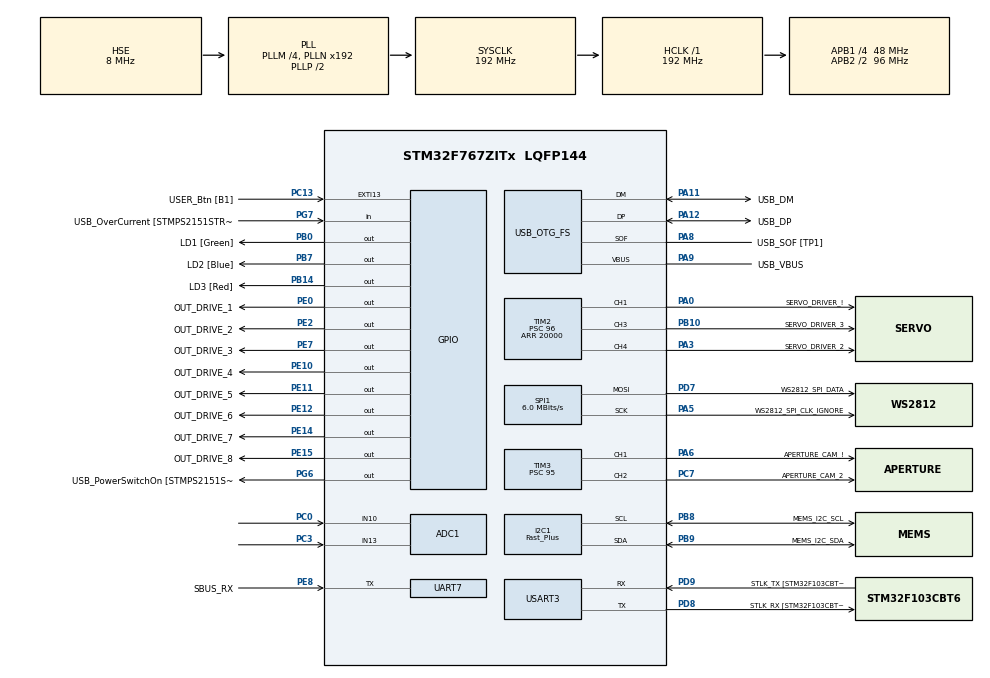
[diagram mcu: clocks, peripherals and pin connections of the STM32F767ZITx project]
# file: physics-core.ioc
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ADC1.Channel-0\#ChannelRegularConversion=ADC_CHANNEL_10
ADC1.NbrOfConversionFlag=1
ADC1.Rank-0\#ChannelRegularConversion=1
ADC1.SamplingTime-0\#ChannelRegularConversion=ADC_SAMPLETIME_3CYCLES
ADC1.master=1
CORTEX_M7.CPU_DCache=Enabled
CORTEX_M7.CPU_ICache=Enabled
CORTEX_M7.FlashInterface=TCM_Enabled
CRC.CRCLength=CRC_POLYLENGTH_16B
CRC.DefaultInitValueUse=DEFAULT_INIT_VALUE_DISABLE
CRC.DefaultPolynomialUse=DEFAULT_POLYNOMIAL_DISABLE
CRC.GeneratingPolynomial=X12+X5+X0
CRC.InitValue=0xffff
Dma.I2C1_RX.1.Direction=DMA_PERIPH_TO_MEMORY
Dma.I2C1_RX.1.FIFOMode=DMA_FIFOMODE_DISABLE
Dma.I2C1_RX.1.Instance=DMA1_Stream0
Dma.I2C1_RX.1.MemDataAlignment=DMA_MDATAALIGN_BYTE
Dma.I2C1_RX.1.MemInc=DMA_MINC_ENABLE
Dma.I2C1_RX.1.Mode=DMA_NORMAL
Dma.I2C1_RX.1.PeriphDataAlignment=DMA_PDATAALIGN_BYTE
Dma.I2C1_RX.1.PeriphInc=DMA_PINC_DISABLE
Dma.I2C1_RX.1.Priority=DMA_PRIORITY_HIGH
Dma.Request0=TIM8_UP
Dma.Request1=I2C1_RX
Dma.Request2=SPI1_TX
Dma.Request3=USART3_TX
Dma.Request4=UART7_RX
Dma.SPI1_TX.2.Direction=DMA_MEMORY_TO_PERIPH
Dma.SPI1_TX.2.FIFOMode=DMA_FIFOMODE_ENABLE
Dma.SPI1_TX.2.FIFOThreshold=DMA_FIFO_THRESHOLD_FULL
Dma.SPI1_TX.2.Instance=DMA2_Stream3
Dma.SPI1_TX.2.MemBurst=DMA_MBURST_INC16
Dma.SPI1_TX.2.MemDataAlignment=DMA_MDATAALIGN_BYTE
Dma.SPI1_TX.2.MemInc=DMA_MINC_ENABLE
Dma.SPI1_TX.2.Mode=DMA_NORMAL
Dma.SPI1_TX.2.PeriphBurst=DMA_PBURST_SINGLE
Dma.SPI1_TX.2.PeriphDataAlignment=DMA_PDATAALIGN_BYTE
Dma.SPI1_TX.2.PeriphInc=DMA_PINC_DISABLE
Dma.SPI1_TX.2.Priority=DMA_PRIORITY_LOW
Dma.TIM8_UP.0.Direction=DMA_MEMORY_TO_PERIPH
Dma.TIM8_UP.0.FIFOMode=DMA_FIFOMODE_ENABLE
Dma.TIM8_UP.0.FIFOThreshold=DMA_FIFO_THRESHOLD_FULL
Dma.TIM8_UP.0.Instance=DMA2_Stream1
Dma.TIM8_UP.0.MemBurst=DMA_MBURST_INC4
Dma.TIM8_UP.0.MemDataAlignment=DMA_MDATAALIGN_WORD
Dma.TIM8_UP.0.MemInc=DMA_MINC_ENABLE
Dma.TIM8_UP.0.Mode=DMA_NORMAL
Dma.TIM8_UP.0.PeriphBurst=DMA_PBURST_SINGLE
Dma.TIM8_UP.0.PeriphDataAlignment=DMA_PDATAALIGN_WORD
Dma.TIM8_UP.0.PeriphInc=DMA_PINC_DISABLE
Dma.TIM8_UP.0.Priority=DMA_PRIORITY_VERY_HIGH
Dma.UART7_RX.4.Direction=DMA_PERIPH_TO_MEMORY
Dma.UART7_RX.4.FIFOMode=DMA_FIFOMODE_DISABLE
Dma.UART7_RX.4.Instance=DMA1_Stream3
Dma.UART7_RX.4.MemDataAlignment=DMA_MDATAALIGN_HALFWORD
Dma.UART7_RX.4.MemInc=DMA_MINC_ENABLE
Dma.UART7_RX.4.Mode=DMA_CIRCULAR
Dma.UART7_RX.4.PeriphDataAlignment=DMA_PDATAALIGN_HALFWORD
Dma.UART7_RX.4.PeriphInc=DMA_PINC_DISABLE
Dma.UART7_RX.4.Priority=DMA_PRIORITY_VERY_HIGH
Dma.USART3_TX.3.Direction=DMA_MEMORY_TO_PERIPH
Dma.USART3_TX.3.FIFOMode=DMA_FIFOMODE_ENABLE
Dma.USART3_TX.3.FIFOThreshold=DMA_FIFO_THRESHOLD_FULL
Dma.USART3_TX.3.Instance=DMA1_Stream4
Dma.USART3_TX.3.MemBurst=DMA_MBURST_SINGLE
Dma.USART3_TX.3.MemDataAlignment=DMA_MDATAALIGN_BYTE
Dma.USART3_TX.3.MemInc=DMA_MINC_ENABLE
Dma.USART3_TX.3.Mode=DMA_NORMAL
Dma.USART3_TX.3.PeriphBurst=DMA_PBURST_SINGLE
Dma.USART3_TX.3.PeriphDataAlignment=DMA_PDATAALIGN_BYTE
Dma.USART3_TX.3.PeriphInc=DMA_PINC_DISABLE
Dma.USART3_TX.3.Priority=DMA_PRIORITY_LOW
I2C1.I2C_Speed_Mode=I2C_Fast_Plus
I2C1.Timing=0x20000209
Mcu.Family=STM32F7
Mcu.Name=STM32F767ZITx
Mcu.Package=LQFP144
NVIC.DMA1_Stream0_IRQn=true\:0\:0\:false\:false\:true\:false\:true
NVIC.DMA1_Stream3_IRQn=true\:0\:0\:false\:false\:true\:false\:true
NVIC.DMA1_Stream4_IRQn=true\:0\:0\:false\:false\:true\:false\:true
NVIC.DMA2_Stream1_IRQn=true\:0\:0\:false\:false\:true\:false\:true
NVIC.DMA2_Stream3_IRQn=true\:0\:0\:false\:false\:true\:false\:true
NVIC.OTG_FS_IRQn=true\:0\:0\:false\:false\:true\:false\:true
NVIC.PriorityGroup=NVIC_PRIORITYGROUP_4
NVIC.UART7_IRQn=true\:0\:0\:false\:false\:true\:true\:true
PA0/WKUP.GPIO_Label=SERVO_DRIVER_\!
PA0/WKUP.Signal=S_TIM2_CH1_ETR
PA1.GPIO_Label=RMII_REF_CLK [LAN8742A-CZ-TR_REFCLK0]
PA1.Signal=ETH_REF_CLK
PA10.GPIO_Label=USB_ID
PA10.Signal=USB_OTG_FS_ID
PA11.GPIO_Label=USB_DM
PA11.Mode=Device_Only
PA11.Signal=USB_OTG_FS_DM
PA12.GPIO_Label=USB_DP
PA12.Mode=Device_Only
PA12.Signal=USB_OTG_FS_DP
PA13.GPIO_Label=TMS
PA13.Mode=Serial_Wire
PA13.Signal=SYS_JTMS-SWDIO
PA14.GPIO_Label=TCK
PA14.Mode=Serial_Wire
PA14.Signal=SYS_JTCK-SWCLK
PA2.GPIO_Label=RMII_MDIO [LAN8742A-CZ-TR_MDIO]
PA2.Signal=ETH_MDIO
PA3.GPIO_Label=SERVO_DRIVER_2
PA3.Signal=S_TIM2_CH4
PA5.GPIO_Label=WS2812_SPI_CLK_IGNORE
PA5.Mode=TX_Only_Simplex_Unidirect_Master
PA5.Signal=SPI1_SCK
PA6.GPIO_Label=APERTURE_CAM_\!
PA6.GPIO_Speed=GPIO_SPEED_FREQ_VERY_HIGH
PA6.Signal=S_TIM3_CH1
PA7.GPIO_Label=RMII_CRS_DV [LAN8742A-CZ-TR_CRS_DV]
PA7.Signal=ETH_CRS_DV
PA8.GPIO_Label=USB_SOF [TP1]
PA8.Mode=Activate_SOF_FS
PA8.Signal=USB_OTG_FS_SOF
PA9.GPIO_Label=USB_VBUS
PA9.Mode=Activate_VBUS
PA9.Signal=USB_OTG_FS_VBUS
PB0.GPIO_Label=LD1 [Green]
PB0.Signal=GPIO_Output
PB10.GPIO_Label=SERVO_DRIVER_3
PB10.Signal=S_TIM2_CH3
PB13.GPIO_Label=RMII_TXD1 [LAN8742A-CZ-TR_TXD1]
PB13.Signal=ETH_TXD1
PB14.GPIO_Label=LD3 [Red]
PB14.Signal=GPIO_Output
PB3.GPIO_Label=SWO
PB3.Signal=SYS_JTDO-SWO
PB7.GPIO_Label=LD2 [Blue]
PB7.Signal=GPIO_Output
PB8.GPIO_Label=MEMS_I2C_SCL
PB8.Mode=I2C
PB8.Signal=I2C1_SCL
PB9.GPIO_Label=MEMS_I2C_SDA
PB9.Mode=I2C
PB9.Signal=I2C1_SDA
PC0.Signal=ADCx_IN10
PC1.GPIO_Label=RMII_MDC [LAN8742A-CZ-TR_MDC]
PC1.Signal=ETH_MDC
PC13.GPIO_Label=USER_Btn [B1]
PC13.Signal=GPXTI13
PC14/OSC32_IN.Mode=LSE-External-Oscillator
PC14/OSC32_IN.Signal=RCC_OSC32_IN
PC15/OSC32_OUT.Mode=LSE-External-Oscillator
PC15/OSC32_OUT.Signal=RCC_OSC32_OUT
PC3.Signal=ADCx_IN13
PC4.GPIO_Label=RMII_RXD0 [LAN8742A-CZ-TR_RXD0]
PC4.Signal=ETH_RXD0
PC5.GPIO_Label=RMII_RXD1 [LAN8742A-CZ-TR_RXD1]
PC5.Signal=ETH_RXD1
PC7.GPIO_Label=APERTURE_CAM_2
PC7.GPIO_Speed=GPIO_SPEED_FREQ_VERY_HIGH
PC7.Signal=S_TIM3_CH2
PD7.GPIO_Label=WS2812_SPI_DATA
PD7.Mode=TX_Only_Simplex_Unidirect_Master
PD7.Signal=SPI1_MOSI
PD8.GPIO_Label=STLK_RX [STM32F103CBT6_PA3]
PD8.Mode=Asynchronous
PD8.Signal=USART3_TX
PD9.GPIO_Label=STLK_TX [STM32F103CBT6_PA2]
PD9.Mode=Asynchronous
PD9.Signal=USART3_RX
PE0.GPIO_Label=OUT_DRIVE_1
PE0.GPIO_PuPd=GPIO_NOPULL
PE0.GPIO_Speed=GPIO_SPEED_FREQ_HIGH
PE0.Signal=GPIO_Output
PE10.GPIO_Label=OUT_DRIVE_4
PE10.GPIO_Speed=GPIO_SPEED_FREQ_HIGH
PE10.Signal=GPIO_Output
PE11.GPIO_Label=OUT_DRIVE_5
PE11.GPIO_Speed=GPIO_SPEED_FREQ_HIGH
PE11.Signal=GPIO_Output
PE12.GPIO_Label=OUT_DRIVE_6
PE12.GPIO_Speed=GPIO_SPEED_FREQ_HIGH
PE12.Signal=GPIO_Output
PE14.GPIO_Label=OUT_DRIVE_7
PE14.GPIO_Speed=GPIO_SPEED_FREQ_HIGH
PE14.Signal=GPIO_Output
PE15.GPIO_Label=OUT_DRIVE_8
PE15.GPIO_Speed=GPIO_SPEED_FREQ_HIGH
PE15.Signal=GPIO_Output
PE2.GPIO_Label=OUT_DRIVE_2
PE2.GPIO_Speed=GPIO_SPEED_FREQ_HIGH
PE2.Signal=GPIO_Output
PE7.GPIO_Label=OUT_DRIVE_3
PE7.GPIO_Speed=GPIO_SPEED_FREQ_HIGH
PE7.Signal=GPIO_Output
PE8.GPIO_Label=SBUS_RX
PE8.Mode=Half_duplex(single_wire_mode)
PE8.Signal=UART7_TX
PG11.GPIO_Label=RMII_TX_EN [LAN8742A-CZ-TR_TXEN]
PG11.Signal=ETH_TX_EN
PG13.GPIO_Label=RMII_TXD0 [LAN8742A-CZ-TR_TXD0]
PG13.Signal=ETH_TXD0
PG6.GPIO_Label=USB_PowerSwitchOn [STMPS2151STR_EN]
PG6.Signal=GPIO_Output
PG7.GPIO_Label=USB_OverCurrent [STMPS2151STR_FAULT]
PG7.Signal=GPIO_Input
PH0/OSC_IN.GPIO_Label=MCO [STM32F103CBT6_PA8]
PH0/OSC_IN.Mode=HSE-External-Clock-Source
PH0/OSC_IN.Signal=RCC_OSC_IN
PH1/OSC_OUT.Mode=HSE-External-Clock-Source
PH1/OSC_OUT.Signal=RCC_OSC_OUT
ProjectManager.HeapSize=0x2000
ProjectManager.StackSize=0x4000
ProjectManager.TargetToolchain=STM32CubeIDE
RCC.48MHZClocksFreq_Value=24000000
RCC.AHBFreq_Value=192000000
RCC.APB1CLKDivider=RCC_HCLK_DIV4
RCC.APB1Freq_Value=48000000
RCC.APB1TimFreq_Value=96000000
RCC.APB2CLKDivider=RCC_HCLK_DIV2
RCC.APB2Freq_Value=96000000
RCC.APB2TimFreq_Value=192000000
RCC.CortexFreq_Value=192000000
RCC.HCLKFreq_Value=192000000
RCC.HSE_VALUE=8000000
RCC.HSI_VALUE=16000000
RCC.PLLM=4
RCC.PLLMUL=RCC_PLL_MUL9
RCC.PLLQ=8
RCC.PRESCALERUSB=RCC_USBCLKSOURCE_PLL_DIV1_5
RCC.SYSCLKFreq_VALUE=192000000
RCC.SYSCLKSource=RCC_SYSCLKSOURCE_PLLCLK
RCC.SYSCLKSourceVirtual=RCC_SYSCLKSOURCE_PLLCLK
RCC.USBFreq_Value=48000000
RCC.VCOOutputFreq_Value=384000000
SH.ADCx_IN10.0=ADC1_IN10,IN10
SH.ADCx_IN13.0=ADC1_IN13,IN13
SH.S_TIM2_CH1_ETR.0=TIM2_CH1,PWM Generation1 CH1
SH.S_TIM2_CH3.0=TIM2_CH3,PWM Generation3 CH3
SH.S_TIM2_CH4.0=TIM2_CH4,PWM Generation4 CH4
SH.S_TIM3_CH1.0=TIM3_CH1,PWM Generation1 CH1
SH.S_TIM3_CH2.0=TIM3_CH2,PWM Generation2 CH2
SPI1.BaudRatePrescaler=SPI_BAUDRATEPRESCALER_16
SPI1.CalculateBaudRate=6.0 MBits/s
SPI1.DataSize=SPI_DATASIZE_6BIT
SPI1.Direction=SPI_DIRECTION_2LINES
SPI1.Mode=SPI_MODE_MASTER
SPI1.NSSPMode=SPI_NSS_PULSE_DISABLE
SPI1.VirtualType=VM_MASTER
TIM2.AutoReloadPreload=TIM_AUTORELOAD_PRELOAD_ENABLE
TIM2.Channel-PWM\ Generation1\ CH1=TIM_CHANNEL_1
TIM2.Channel-PWM\ Generation3\ CH3=TIM_CHANNEL_3
TIM2.Channel-PWM\ Generation4\ CH4=TIM_CHANNEL_4
TIM2.OC1Preload_PWM=ENABLE
TIM2.OCFastMode_PWM-PWM\ Generation1\ CH1=TIM_OCFAST_ENABLE
TIM2.OCFastMode_PWM-PWM\ Generation3\ CH3=TIM_OCFAST_ENABLE
TIM2.OCFastMode_PWM-PWM\ Generation4\ CH4=TIM_OCFAST_ENABLE
TIM2.Period=20000
TIM2.Prescaler=96
TIM2.Pulse-PWM\ Generation1\ CH1=1500
TIM2.Pulse-PWM\ Generation3\ CH3=1500
TIM2.Pulse-PWM\ Generation4\ CH4=1500
TIM3.AutoReloadPreload=TIM_AUTORELOAD_PRELOAD_ENABLE
TIM3.Channel-PWM\ Generation1\ CH1=TIM_CHANNEL_1
TIM3.Channel-PWM\ Generation2\ CH2=TIM_CHANNEL_2
TIM3.OCFastMode_PWM-PWM\ Generation1\ CH1=TIM_OCFAST_ENABLE
TIM3.OCFastMode_PWM-PWM\ Generation2\ CH2=TIM_OCFAST_ENABLE
TIM3.OCPolarity_1=TIM_OCPOLARITY_HIGH
TIM3.OCPolarity_2=TIM_OCPOLARITY_HIGH
TIM3.Period=99
TIM3.Prescaler=95
TIM3.Pulse-PWM\ Generation1\ CH1=0
TIM3.Pulse-PWM\ Generation2\ CH2=0
TIM8.AutoReloadPreload=TIM_AUTORELOAD_PRELOAD_ENABLE
TIM8.Period=4
TIM8.Prescaler=7
UART7.BaudRate=100000
UART7.DataInvertParam=UART_ADVFEATURE_DATAINV_DISABLE
UART7.Mode=MODE_RX
UART7.Parity=PARITY_EVEN
UART7.RxPinLevelInvertParam=UART_ADVFEATURE_RXINV_ENABLE
UART7.StopBits=UART_STOPBITS_2
UART7.TxPinLevelInvertParam=UART_ADVFEATURE_TXINV_ENABLE
UART7.WordLength=WORDLENGTH_9B
USART3.VirtualMode-Asynchronous=VM_ASYNC
USB_DEVICE.CLASS_NAME_FS=CDC
USB_DEVICE.VirtualMode-CDC_FS=Cdc
USB_DEVICE.VirtualModeFS=Cdc_FS
USB_OTG_FS.VirtualMode=Device_Only
VP_ADC1_TempSens_Input.Mode=IN-TempSens
VP_CRC_VS_CRC.Mode=CRC_Activate
VP_TIM2_VS_ClockSourceINT.Mode=Internal
VP_TIM3_VS_ClockSourceINT.Mode=Internal
VP_TIM8_VS_ClockSourceINT.Mode=Internal
VP_USB_DEVICE_VS_USB_DEVICE_CDC_FS.Mode=CDC_FS
board=NUCLEO-F767ZI

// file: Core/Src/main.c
/* USER CODE BEGIN Header */
/**
 ******************************************************************************
 * @file           : main.c
 * @brief          : Main program body
 ******************************************************************************
 * @attention
 *
 * <h2><center>&copy; Copyright (c) 2020 STMicroelectronics.
 * All rights reserved.</center></h2>
 *
 * This software component is licensed by ST under BSD 3-Clause license,
 * the "License"; You may not use this file except in compliance with the
 * License. You may obtain a copy of the License at:
 *                        opensource.org/licenses/BSD-3-Clause
 *
 ******************************************************************************
 */
/* USER CODE END Header */
#include "main.h"
#include "usb_device.h"

ADC_HandleTypeDef hadc1;

CRC_HandleTypeDef hcrc;

I2C_HandleTypeDef hi2c1;
DMA_HandleTypeDef hdma_i2c1_rx;

SPI_HandleTypeDef hspi1;
DMA_HandleTypeDef hdma_spi1_tx;

TIM_HandleTypeDef htim2;
TIM_HandleTypeDef htim3;
TIM_HandleTypeDef htim8;
DMA_HandleTypeDef hdma_tim8_up;

UART_HandleTypeDef huart7;
UART_HandleTypeDef huart3;
DMA_HandleTypeDef hdma_uart7_rx;
DMA_HandleTypeDef hdma_usart3_tx;

/* USER CODE BEGIN PV */
csm_core_t csmc;
/* USER CODE END PV */

void SystemClock_Config(void);
static void MX_GPIO_Init(void);
static void MX_DMA_Init(void);
static void MX_USART3_UART_Init(void);
static void MX_TIM3_Init(void);
static void MX_CRC_Init(void);
static void MX_TIM8_Init(void);
static void MX_I2C1_Init(void);
static void MX_TIM2_Init(void);
static void MX_SPI1_Init(void);
static void MX_UART7_Init(void);
static void MX_ADC1_Init(void);

int main(void)
{

  /* Enable I-Cache---------------------------------------------------------*/
  SCB_EnableICache();

  /* Enable D-Cache---------------------------------------------------------*/
  SCB_EnableDCache();

  /* MCU Configuration--------------------------------------------------------*/

  /* Reset of all peripherals, Initializes the Flash interface and the Systick. */
  HAL_Init();

  /* Configure the system clock */
  SystemClock_Config();

  /* Initialize all configured peripherals */
  MX_GPIO_Init();
  MX_DMA_Init();
  MX_USART3_UART_Init();
  MX_TIM3_Init();
  MX_USB_DEVICE_Init();
  MX_CRC_Init();
  MX_TIM8_Init();
  MX_I2C1_Init();
  MX_TIM2_Init();
  MX_SPI1_Init();
  MX_UART7_Init();
  MX_ADC1_Init();
  /* USER CODE BEGIN 2 */

	pre_while();
  /* USER CODE END 2 */

  /* Infinite loop */
	while (1) {

    /* USER CODE BEGIN 3 */
		in_while();
	}
  /* USER CODE END 3 */
}

void SystemClock_Config(void)
{
  RCC_OscInitTypeDef RCC_OscInitStruct = {0};
  RCC_ClkInitTypeDef RCC_ClkInitStruct = {0};
  RCC_PeriphCLKInitTypeDef PeriphClkInitStruct = {0};

  /** Configure LSE Drive Capability
  */
  HAL_PWR_EnableBkUpAccess();
  /** Configure the main internal regulator output voltage
  */
  __HAL_RCC_PWR_CLK_ENABLE();
  __HAL_PWR_VOLTAGESCALING_CONFIG(PWR_REGULATOR_VOLTAGE_SCALE1);
  /** Initializes the RCC Oscillators according to the specified parameters
  * in the RCC_OscInitTypeDef structure.
  */
  RCC_OscInitStruct.OscillatorType = RCC_OSCILLATORTYPE_HSE;
  RCC_OscInitStruct.HSEState = RCC_HSE_BYPASS;
  RCC_OscInitStruct.PLL.PLLState = RCC_PLL_ON;
  RCC_OscInitStruct.PLL.PLLSource = RCC_PLLSOURCE_HSE;
  RCC_OscInitStruct.PLL.PLLM = 4;
  RCC_OscInitStruct.PLL.PLLN = 192;
  RCC_OscInitStruct.PLL.PLLP = RCC_PLLP_DIV2;
  RCC_OscInitStruct.PLL.PLLQ = 8;
  if (HAL_RCC_OscConfig(&RCC_OscInitStruct) != HAL_OK)
  {
    Error_Handler();
  }
  /** Activate the Over-Drive mode
  */
  if (HAL_PWREx_EnableOverDrive() != HAL_OK)
  {
    Error_Handler();
  }
  /** Initializes the CPU, AHB and APB buses clocks
  */
  RCC_ClkInitStruct.ClockType = RCC_CLOCKTYPE_HCLK|RCC_CLOCKTYPE_SYSCLK
                              |RCC_CLOCKTYPE_PCLK1|RCC_CLOCKTYPE_PCLK2;
  RCC_ClkInitStruct.SYSCLKSource = RCC_SYSCLKSOURCE_PLLCLK;
  RCC_ClkInitStruct.AHBCLKDivider = RCC_SYSCLK_DIV1;
  RCC_ClkInitStruct.APB1CLKDivider = RCC_HCLK_DIV4;
  RCC_ClkInitStruct.APB2CLKDivider = RCC_HCLK_DIV2;

  if (HAL_RCC_ClockConfig(&RCC_ClkInitStruct, FLASH_LATENCY_6) != HAL_OK)
  {
    Error_Handler();
  }
  PeriphClkInitStruct.PeriphClockSelection = RCC_PERIPHCLK_USART3|RCC_PERIPHCLK_UART7
                              |RCC_PERIPHCLK_I2C1|RCC_PERIPHCLK_CLK48;
  PeriphClkInitStruct.Usart3ClockSelection = RCC_USART3CLKSOURCE_PCLK1;
  PeriphClkInitStruct.Uart7ClockSelection = RCC_UART7CLKSOURCE_PCLK1;
  PeriphClkInitStruct.I2c1ClockSelection = RCC_I2C1CLKSOURCE_PCLK1;
  PeriphClkInitStruct.Clk48ClockSelection = RCC_CLK48SOURCE_PLL;
  if (HAL_RCCEx_PeriphCLKConfig(&PeriphClkInitStruct) != HAL_OK)
  {
    Error_Handler();
  }
}

static void MX_ADC1_Init(void)
{

  ADC_ChannelConfTypeDef sConfig = {0};

  /** Configure the global features of the ADC (Clock, Resolution, Data Alignment and number of conversion)
  */
  hadc1.Instance = ADC1;
  hadc1.Init.ClockPrescaler = ADC_CLOCK_SYNC_PCLK_DIV4;
  hadc1.Init.Resolution = ADC_RESOLUTION_12B;
  hadc1.Init.ScanConvMode = ADC_SCAN_DISABLE;
  hadc1.Init.ContinuousConvMode = DISABLE;
  hadc1.Init.DiscontinuousConvMode = DISABLE;
  hadc1.Init.ExternalTrigConvEdge = ADC_EXTERNALTRIGCONVEDGE_NONE;
  hadc1.Init.ExternalTrigConv = ADC_SOFTWARE_START;
  hadc1.Init.DataAlign = ADC_DATAALIGN_RIGHT;
  hadc1.Init.NbrOfConversion = 1;
  hadc1.Init.DMAContinuousRequests = DISABLE;
  hadc1.Init.EOCSelection = ADC_EOC_SINGLE_CONV;
  if (HAL_ADC_Init(&hadc1) != HAL_OK)
  {
    Error_Handler();
  }
  /** Configure for the selected ADC regular channel its corresponding rank in the sequencer and its sample time.
  */
  sConfig.Channel = ADC_CHANNEL_10;
  sConfig.Rank = ADC_REGULAR_RANK_1;
  sConfig.SamplingTime = ADC_SAMPLETIME_3CYCLES;
  if (HAL_ADC_ConfigChannel(&hadc1, &sConfig) != HAL_OK)
  {
    Error_Handler();
  }

}

static void MX_CRC_Init(void)
{

  hcrc.Instance = CRC;
  hcrc.Init.DefaultPolynomialUse = DEFAULT_POLYNOMIAL_DISABLE;
  hcrc.Init.DefaultInitValueUse = DEFAULT_INIT_VALUE_DISABLE;
  hcrc.Init.GeneratingPolynomial = 4129;
  hcrc.Init.CRCLength = CRC_POLYLENGTH_16B;
  hcrc.Init.InitValue = 0xffff;
  hcrc.Init.InputDataInversionMode = CRC_INPUTDATA_INVERSION_NONE;
  hcrc.Init.OutputDataInversionMode = CRC_OUTPUTDATA_INVERSION_DISABLE;
  hcrc.InputDataFormat = CRC_INPUTDATA_FORMAT_BYTES;
  if (HAL_CRC_Init(&hcrc) != HAL_OK)
  {
    Error_Handler();
  }

}

static void MX_I2C1_Init(void)
{

  hi2c1.Instance = I2C1;
  hi2c1.Init.Timing = 0x20000209;
  hi2c1.Init.OwnAddress1 = 0;
  hi2c1.Init.AddressingMode = I2C_ADDRESSINGMODE_7BIT;
  hi2c1.Init.DualAddressMode = I2C_DUALADDRESS_DISABLE;
  hi2c1.Init.OwnAddress2 = 0;
  hi2c1.Init.OwnAddress2Masks = I2C_OA2_NOMASK;
  hi2c1.Init.GeneralCallMode = I2C_GENERALCALL_DISABLE;
  hi2c1.Init.NoStretchMode = I2C_NOSTRETCH_DISABLE;
  if (HAL_I2C_Init(&hi2c1) != HAL_OK)
  {
    Error_Handler();
  }
  /** Configure Analogue filter
  */
  if (HAL_I2CEx_ConfigAnalogFilter(&hi2c1, I2C_ANALOGFILTER_ENABLE) != HAL_OK)
  {
    Error_Handler();
  }
  /** Configure Digital filter
  */
  if (HAL_I2CEx_ConfigDigitalFilter(&hi2c1, 0) != HAL_OK)
  {
    Error_Handler();
  }
  /** I2C Enable Fast Mode Plus
  */
  HAL_I2CEx_EnableFastModePlus(I2C_FASTMODEPLUS_I2C1);

}

static void MX_SPI1_Init(void)
{

  /* SPI1 parameter configuration*/
  hspi1.Instance = SPI1;
  hspi1.Init.Mode = SPI_MODE_MASTER;
  hspi1.Init.Direction = SPI_DIRECTION_2LINES;
  hspi1.Init.DataSize = SPI_DATASIZE_6BIT;
  hspi1.Init.CLKPolarity = SPI_POLARITY_LOW;
  hspi1.Init.CLKPhase = SPI_PHASE_1EDGE;
  hspi1.Init.NSS = SPI_NSS_SOFT;
  hspi1.Init.BaudRatePrescaler = SPI_BAUDRATEPRESCALER_16;
  hspi1.Init.FirstBit = SPI_FIRSTBIT_MSB;
  hspi1.Init.TIMode = SPI_TIMODE_DISABLE;
  hspi1.Init.CRCCalculation = SPI_CRCCALCULATION_DISABLE;
  hspi1.Init.CRCPolynomial = 7;
  hspi1.Init.CRCLength = SPI_CRC_LENGTH_DATASIZE;
  hspi1.Init.NSSPMode = SPI_NSS_PULSE_DISABLE;
  if (HAL_SPI_Init(&hspi1) != HAL_OK)
  {
    Error_Handler();
  }

}

static void MX_TIM2_Init(void)
{

  TIM_ClockConfigTypeDef sClockSourceConfig = {0};
  TIM_MasterConfigTypeDef sMasterConfig = {0};
  TIM_OC_InitTypeDef sConfigOC = {0};

  htim2.Instance = TIM2;
  htim2.Init.Prescaler = 96;
  htim2.Init.CounterMode = TIM_COUNTERMODE_UP;
  htim2.Init.Period = 20000;
  htim2.Init.ClockDivision = TIM_CLOCKDIVISION_DIV1;
  htim2.Init.AutoReloadPreload = TIM_AUTORELOAD_PRELOAD_ENABLE;
  if (HAL_TIM_Base_Init(&htim2) != HAL_OK)
  {
    Error_Handler();
  }
  sClockSourceConfig.ClockSource = TIM_CLOCKSOURCE_INTERNAL;
  if (HAL_TIM_ConfigClockSource(&htim2, &sClockSourceConfig) != HAL_OK)
  {
    Error_Handler();
  }
  if (HAL_TIM_PWM_Init(&htim2) != HAL_OK)
  {
    Error_Handler();
  }
  sMasterConfig.MasterOutputTrigger = TIM_TRGO_RESET;
  sMasterConfig.MasterSlaveMode = TIM_MASTERSLAVEMODE_DISABLE;
  if (HAL_TIMEx_MasterConfigSynchronization(&htim2, &sMasterConfig) != HAL_OK)
  {
    Error_Handler();
  }
  sConfigOC.OCMode = TIM_OCMODE_PWM1;
  sConfigOC.Pulse = 1500;
  sConfigOC.OCPolarity = TIM_OCPOLARITY_HIGH;
  sConfigOC.OCFastMode = TIM_OCFAST_ENABLE;
  if (HAL_TIM_PWM_ConfigChannel(&htim2, &sConfigOC, TIM_CHANNEL_1) != HAL_OK)
  {
    Error_Handler();
  }
  if (HAL_TIM_PWM_ConfigChannel(&htim2, &sConfigOC, TIM_CHANNEL_3) != HAL_OK)
  {
    Error_Handler();
  }
  if (HAL_TIM_PWM_ConfigChannel(&htim2, &sConfigOC, TIM_CHANNEL_4) != HAL_OK)
  {
    Error_Handler();
  }
  HAL_TIM_MspPostInit(&htim2);

}

static void MX_TIM3_Init(void)
{

  TIM_ClockConfigTypeDef sClockSourceConfig = {0};
  TIM_MasterConfigTypeDef sMasterConfig = {0};
  TIM_OC_InitTypeDef sConfigOC = {0};

  htim3.Instance = TIM3;
  htim3.Init.Prescaler = 95;
  htim3.Init.CounterMode = TIM_COUNTERMODE_UP;
  htim3.Init.Period = 99;
  htim3.Init.ClockDivision = TIM_CLOCKDIVISION_DIV1;
  htim3.Init.AutoReloadPreload = TIM_AUTORELOAD_PRELOAD_ENABLE;
  if (HAL_TIM_Base_Init(&htim3) != HAL_OK)
  {
    Error_Handler();
  }
  sClockSourceConfig.ClockSource = TIM_CLOCKSOURCE_INTERNAL;
  if (HAL_TIM_ConfigClockSource(&htim3, &sClockSourceConfig) != HAL_OK)
  {
    Error_Handler();
  }
  if (HAL_TIM_PWM_Init(&htim3) != HAL_OK)
  {
    Error_Handler();
  }
  sMasterConfig.MasterOutputTrigger = TIM_TRGO_RESET;
  sMasterConfig.MasterSlaveMode = TIM_MASTERSLAVEMODE_DISABLE;
  if (HAL_TIMEx_MasterConfigSynchronization(&htim3, &sMasterConfig) != HAL_OK)
  {
    Error_Handler();
  }
  sConfigOC.OCMode = TIM_OCMODE_PWM1;
  sConfigOC.Pulse = 0;
  sConfigOC.OCPolarity = TIM_OCPOLARITY_HIGH;
  sConfigOC.OCFastMode = TIM_OCFAST_ENABLE;
  if (HAL_TIM_PWM_ConfigChannel(&htim3, &sConfigOC, TIM_CHANNEL_1) != HAL_OK)
  {
    Error_Handler();
  }
  if (HAL_TIM_PWM_ConfigChannel(&htim3, &sConfigOC, TIM_CHANNEL_2) != HAL_OK)
  {
    Error_Handler();
  }
  HAL_TIM_MspPostInit(&htim3);

}

static void MX_TIM8_Init(void)
{

  TIM_ClockConfigTypeDef sClockSourceConfig = {0};
  TIM_MasterConfigTypeDef sMasterConfig = {0};

  htim8.Instance = TIM8;
  htim8.Init.Prescaler = 7;
  htim8.Init.CounterMode = TIM_COUNTERMODE_UP;
  htim8.Init.Period = 4;
  htim8.Init.ClockDivision = TIM_CLOCKDIVISION_DIV1;
  htim8.Init.RepetitionCounter = 0;
  htim8.Init.AutoReloadPreload = TIM_AUTORELOAD_PRELOAD_ENABLE;
  if (HAL_TIM_Base_Init(&htim8) != HAL_OK)
  {
    Error_Handler();
  }
  sClockSourceConfig.ClockSource = TIM_CLOCKSOURCE_INTERNAL;
  if (HAL_TIM_ConfigClockSource(&htim8, &sClockSourceConfig) != HAL_OK)
  {
    Error_Handler();
  }
  sMasterConfig.MasterOutputTrigger = TIM_TRGO_RESET;
  sMasterConfig.MasterOutputTrigger2 = TIM_TRGO2_RESET;
  sMasterConfig.MasterSlaveMode = TIM_MASTERSLAVEMODE_DISABLE;
  if (HAL_TIMEx_MasterConfigSynchronization(&htim8, &sMasterConfig) != HAL_OK)
  {
    Error_Handler();
  }

}

static void MX_UART7_Init(void)
{

  huart7.Instance = UART7;
  huart7.Init.BaudRate = 100000;
  huart7.Init.WordLength = UART_WORDLENGTH_9B;
  huart7.Init.StopBits = UART_STOPBITS_2;
  huart7.Init.Parity = UART_PARITY_EVEN;
  huart7.Init.Mode = UART_MODE_RX;
  huart7.Init.HwFlowCtl = UART_HWCONTROL_NONE;
  huart7.Init.OverSampling = UART_OVERSAMPLING_16;
  huart7.Init.OneBitSampling = UART_ONE_BIT_SAMPLE_DISABLE;
  huart7.AdvancedInit.AdvFeatureInit = UART_ADVFEATURE_TXINVERT_INIT|UART_ADVFEATURE_RXINVERT_INIT;
  huart7.AdvancedInit.TxPinLevelInvert = UART_ADVFEATURE_TXINV_ENABLE;
  huart7.AdvancedInit.RxPinLevelInvert = UART_ADVFEATURE_RXINV_ENABLE;
  if (HAL_HalfDuplex_Init(&huart7) != HAL_OK)
  {
    Error_Handler();
  }

}

static void MX_USART3_UART_Init(void)
{

  huart3.Instance = USART3;
  huart3.Init.BaudRate = 115200;
  huart3.Init.WordLength = UART_WORDLENGTH_8B;
  huart3.Init.StopBits = UART_STOPBITS_1;
  huart3.Init.Parity = UART_PARITY_NONE;
  huart3.Init.Mode = UART_MODE_TX_RX;
  huart3.Init.HwFlowCtl = UART_HWCONTROL_NONE;
  huart3.Init.OverSampling = UART_OVERSAMPLING_16;
  huart3.Init.OneBitSampling = UART_ONE_BIT_SAMPLE_DISABLE;
  huart3.AdvancedInit.AdvFeatureInit = UART_ADVFEATURE_NO_INIT;
  if (HAL_UART_Init(&huart3) != HAL_OK)
  {
    Error_Handler();
  }

}

static void MX_DMA_Init(void)
{

  /* DMA controller clock enable */
  __HAL_RCC_DMA2_CLK_ENABLE();
  __HAL_RCC_DMA1_CLK_ENABLE();

  /* DMA interrupt init */
  /* DMA1_Stream0_IRQn interrupt configuration */
  HAL_NVIC_SetPriority(DMA1_Stream0_IRQn, 0, 0);
  HAL_NVIC_EnableIRQ(DMA1_Stream0_IRQn);
  /* DMA1_Stream3_IRQn interrupt configuration */
  HAL_NVIC_SetPriority(DMA1_Stream3_IRQn, 0, 0);
  HAL_NVIC_EnableIRQ(DMA1_Stream3_IRQn);
  /* DMA1_Stream4_IRQn interrupt configuration */
  HAL_NVIC_SetPriority(DMA1_Stream4_IRQn, 0, 0);
  HAL_NVIC_EnableIRQ(DMA1_Stream4_IRQn);
  /* DMA2_Stream1_IRQn interrupt configuration */
  HAL_NVIC_SetPriority(DMA2_Stream1_IRQn, 0, 0);
  HAL_NVIC_EnableIRQ(DMA2_Stream1_IRQn);
  /* DMA2_Stream3_IRQn interrupt configuration */
  HAL_NVIC_SetPriority(DMA2_Stream3_IRQn, 0, 0);
  HAL_NVIC_EnableIRQ(DMA2_Stream3_IRQn);

}

static void MX_GPIO_Init(void)
{
  GPIO_InitTypeDef GPIO_InitStruct = {0};

  /* GPIO Ports Clock Enable */
  __HAL_RCC_GPIOE_CLK_ENABLE();
  __HAL_RCC_GPIOC_CLK_ENABLE();
  __HAL_RCC_GPIOF_CLK_ENABLE();
  __HAL_RCC_GPIOH_CLK_ENABLE();
  __HAL_RCC_GPIOA_CLK_ENABLE();
  __HAL_RCC_GPIOB_CLK_ENABLE();
  __HAL_RCC_GPIOG_CLK_ENABLE();
  __HAL_RCC_GPIOD_CLK_ENABLE();

  /*Configure GPIO pin Output Level */
  HAL_GPIO_WritePin(GPIOE, OUT_DRIVE_2_Pin|OUT_DRIVE_3_Pin|OUT_DRIVE_4_Pin|OUT_DRIVE_5_Pin
                          |OUT_DRIVE_6_Pin|OUT_DRIVE_7_Pin|OUT_DRIVE_8_Pin|OUT_DRIVE_1_Pin, GPIO_PIN_RESET);

  /*Configure GPIO pin Output Level */
  HAL_GPIO_WritePin(GPIOB, LD1_Pin|LD3_Pin|LD2_Pin, GPIO_PIN_RESET);

  /*Configure GPIO pin Output Level */
  HAL_GPIO_WritePin(USB_PowerSwitchOn_GPIO_Port, USB_PowerSwitchOn_Pin, GPIO_PIN_RESET);

  /*Configure GPIO pins : OUT_DRIVE_2_Pin OUT_DRIVE_3_Pin OUT_DRIVE_4_Pin OUT_DRIVE_5_Pin
                           OUT_DRIVE_6_Pin OUT_DRIVE_7_Pin OUT_DRIVE_8_Pin OUT_DRIVE_1_Pin */
  GPIO_InitStruct.Pin = OUT_DRIVE_2_Pin|OUT_DRIVE_3_Pin|OUT_DRIVE_4_Pin|OUT_DRIVE_5_Pin
                          |OUT_DRIVE_6_Pin|OUT_DRIVE_7_Pin|OUT_DRIVE_8_Pin|OUT_DRIVE_1_Pin;
  GPIO_InitStruct.Mode = GPIO_MODE_OUTPUT_PP;
  GPIO_InitStruct.Pull = GPIO_NOPULL;
  GPIO_InitStruct.Speed = GPIO_SPEED_FREQ_HIGH;
  HAL_GPIO_Init(GPIOE, &GPIO_InitStruct);

  /*Configure GPIO pins : PE3 PE4 PE5 PE6
                           PE9 PE13 PE1 */
  GPIO_InitStruct.Pin = GPIO_PIN_3|GPIO_PIN_4|GPIO_PIN_5|GPIO_PIN_6
                          |GPIO_PIN_9|GPIO_PIN_13|GPIO_PIN_1;
  GPIO_InitStruct.Mode = GPIO_MODE_ANALOG;
  GPIO_InitStruct.Pull = GPIO_NOPULL;
  HAL_GPIO_Init(GPIOE, &GPIO_InitStruct);

  /*Configure GPIO pin : USER_Btn_Pin */
  GPIO_InitStruct.Pin = USER_Btn_Pin;
  GPIO_InitStruct.Mode = GPIO_MODE_IT_RISING;
  GPIO_InitStruct.Pull = GPIO_NOPULL;
  HAL_GPIO_Init(USER_Btn_GPIO_Port, &GPIO_InitStruct);

  /*Configure GPIO pins : PF0 PF1 PF2 PF3
                           PF4 PF5 PF6 PF7
                           PF8 PF9 PF10 PF11
                           PF12 PF13 PF14 PF15 */
  GPIO_InitStruct.Pin = GPIO_PIN_0|GPIO_PIN_1|GPIO_PIN_2|GPIO_PIN_3
                          |GPIO_PIN_4|GPIO_PIN_5|GPIO_PIN_6|GPIO_PIN_7
                          |GPIO_PIN_8|GPIO_PIN_9|GPIO_PIN_10|GPIO_PIN_11
                          |GPIO_PIN_12|GPIO_PIN_13|GPIO_PIN_14|GPIO_PIN_15;
  GPIO_InitStruct.Mode = GPIO_MODE_ANALOG;
  GPIO_InitStruct.Pull = GPIO_NOPULL;
  HAL_GPIO_Init(GPIOF, &GPIO_InitStruct);

  /*Configure GPIO pins : RMII_MDC_Pin RMII_RXD0_Pin RMII_RXD1_Pin */
  GPIO_InitStruct.Pin = RMII_MDC_Pin|RMII_RXD0_Pin|RMII_RXD1_Pin;
  GPIO_InitStruct.Mode = GPIO_MODE_AF_PP;
  GPIO_InitStruct.Pull = GPIO_NOPULL;
  GPIO_InitStruct.Speed = GPIO_SPEED_FREQ_VERY_HIGH;
  GPIO_InitStruct.Alternate = GPIO_AF11_ETH;
  HAL_GPIO_Init(GPIOC, &GPIO_InitStruct);

  /*Configure GPIO pins : PC2 PC6 PC8 PC9
                           PC10 PC11 PC12 */
  GPIO_InitStruct.Pin = GPIO_PIN_2|GPIO_PIN_6|GPIO_PIN_8|GPIO_PIN_9
                          |GPIO_PIN_10|GPIO_PIN_11|GPIO_PIN_12;
  GPIO_InitStruct.Mode = GPIO_MODE_ANALOG;
  GPIO_InitStruct.Pull = GPIO_NOPULL;
  HAL_GPIO_Init(GPIOC, &GPIO_InitStruct);

  /*Configure GPIO pins : RMII_REF_CLK_Pin RMII_MDIO_Pin RMII_CRS_DV_Pin */
  GPIO_InitStruct.Pin = RMII_REF_CLK_Pin|RMII_MDIO_Pin|RMII_CRS_DV_Pin;
  GPIO_InitStruct.Mode = GPIO_MODE_AF_PP;
  GPIO_InitStruct.Pull = GPIO_NOPULL;
  GPIO_InitStruct.Speed = GPIO_SPEED_FREQ_VERY_HIGH;
  GPIO_InitStruct.Alternate = GPIO_AF11_ETH;
  HAL_GPIO_Init(GPIOA, &GPIO_InitStruct);

  /*Configure GPIO pins : PA4 PA15 */
  GPIO_InitStruct.Pin = GPIO_PIN_4|GPIO_PIN_15;
  GPIO_InitStruct.Mode = GPIO_MODE_ANALOG;
  GPIO_InitStruct.Pull = GPIO_NOPULL;
  HAL_GPIO_Init(GPIOA, &GPIO_InitStruct);

  /*Configure GPIO pins : LD1_Pin LD3_Pin LD2_Pin */
  GPIO_InitStruct.Pin = LD1_Pin|LD3_Pin|LD2_Pin;
  GPIO_InitStruct.Mode = GPIO_MODE_OUTPUT_PP;
  GPIO_InitStruct.Pull = GPIO_NOPULL;
  GPIO_InitStruct.Speed = GPIO_SPEED_FREQ_LOW;
  HAL_GPIO_Init(GPIOB, &GPIO_InitStruct);

  /*Configure GPIO pins : PB1 PB2 PB11 PB12
                           PB15 PB4 PB5 PB6 */
  GPIO_InitStruct.Pin = GPIO_PIN_1|GPIO_PIN_2|GPIO_PIN_11|GPIO_PIN_12
                          |GPIO_PIN_15|GPIO_PIN_4|GPIO_PIN_5|GPIO_PIN_6;
  GPIO_InitStruct.Mode = GPIO_MODE_ANALOG;
  GPIO_InitStruct.Pull = GPIO_NOPULL;
  HAL_GPIO_Init(GPIOB, &GPIO_InitStruct);

  /*Configure GPIO pins : PG0 PG1 PG2 PG3
                           PG4 PG5 PG8 PG9
                           PG10 PG12 PG14 PG15 */
  GPIO_InitStruct.Pin = GPIO_PIN_0|GPIO_PIN_1|GPIO_PIN_2|GPIO_PIN_3
                          |GPIO_PIN_4|GPIO_PIN_5|GPIO_PIN_8|GPIO_PIN_9
                          |GPIO_PIN_10|GPIO_PIN_12|GPIO_PIN_14|GPIO_PIN_15;
  GPIO_InitStruct.Mode = GPIO_MODE_ANALOG;
  GPIO_InitStruct.Pull = GPIO_NOPULL;
  HAL_GPIO_Init(GPIOG, &GPIO_InitStruct);

  /*Configure GPIO pin : RMII_TXD1_Pin */
  GPIO_InitStruct.Pin = RMII_TXD1_Pin;
  GPIO_InitStruct.Mode = GPIO_MODE_AF_PP;
  GPIO_InitStruct.Pull = GPIO_NOPULL;
  GPIO_InitStruct.Speed = GPIO_SPEED_FREQ_VERY_HIGH;
  GPIO_InitStruct.Alternate = GPIO_AF11_ETH;
  HAL_GPIO_Init(RMII_TXD1_GPIO_Port, &GPIO_InitStruct);

  /*Configure GPIO pins : PD10 PD11 PD12 PD13
                           PD14 PD15 PD0 PD1
                           PD2 PD3 PD4 PD5
                           PD6 */
  GPIO_InitStruct.Pin = GPIO_PIN_10|GPIO_PIN_11|GPIO_PIN_12|GPIO_PIN_13
                          |GPIO_PIN_14|GPIO_PIN_15|GPIO_PIN_0|GPIO_PIN_1
                          |GPIO_PIN_2|GPIO_PIN_3|GPIO_PIN_4|GPIO_PIN_5
                          |GPIO_PIN_6;
  GPIO_InitStruct.Mode = GPIO_MODE_ANALOG;
  GPIO_InitStruct.Pull = GPIO_NOPULL;
  HAL_GPIO_Init(GPIOD, &GPIO_InitStruct);

  /*Configure GPIO pin : USB_PowerSwitchOn_Pin */
  GPIO_InitStruct.Pin = USB_PowerSwitchOn_Pin;
  GPIO_InitStruct.Mode = GPIO_MODE_OUTPUT_PP;
  GPIO_InitStruct.Pull = GPIO_NOPULL;
  GPIO_InitStruct.Speed = GPIO_SPEED_FREQ_LOW;
  HAL_GPIO_Init(USB_PowerSwitchOn_GPIO_Port, &GPIO_InitStruct);

  /*Configure GPIO pin : USB_OverCurrent_Pin */
  GPIO_InitStruct.Pin = USB_OverCurrent_Pin;
  GPIO_InitStruct.Mode = GPIO_MODE_INPUT;
  GPIO_InitStruct.Pull = GPIO_NOPULL;
  HAL_GPIO_Init(USB_OverCurrent_GPIO_Port, &GPIO_InitStruct);

  /*Configure GPIO pins : RMII_TX_EN_Pin RMII_TXD0_Pin */
  GPIO_InitStruct.Pin = RMII_TX_EN_Pin|RMII_TXD0_Pin;
  GPIO_InitStruct.Mode = GPIO_MODE_AF_PP;
  GPIO_InitStruct.Pull = GPIO_NOPULL;
  GPIO_InitStruct.Speed = GPIO_SPEED_FREQ_VERY_HIGH;
  GPIO_InitStruct.Alternate = GPIO_AF11_ETH;
  HAL_GPIO_Init(GPIOG, &GPIO_InitStruct);

}

void Error_Handler(void)
{
	__disable_irq();
	while (1) {
	}
}

/************************ (C) COPYRIGHT STMicroelectronics *****END OF FILE****/
